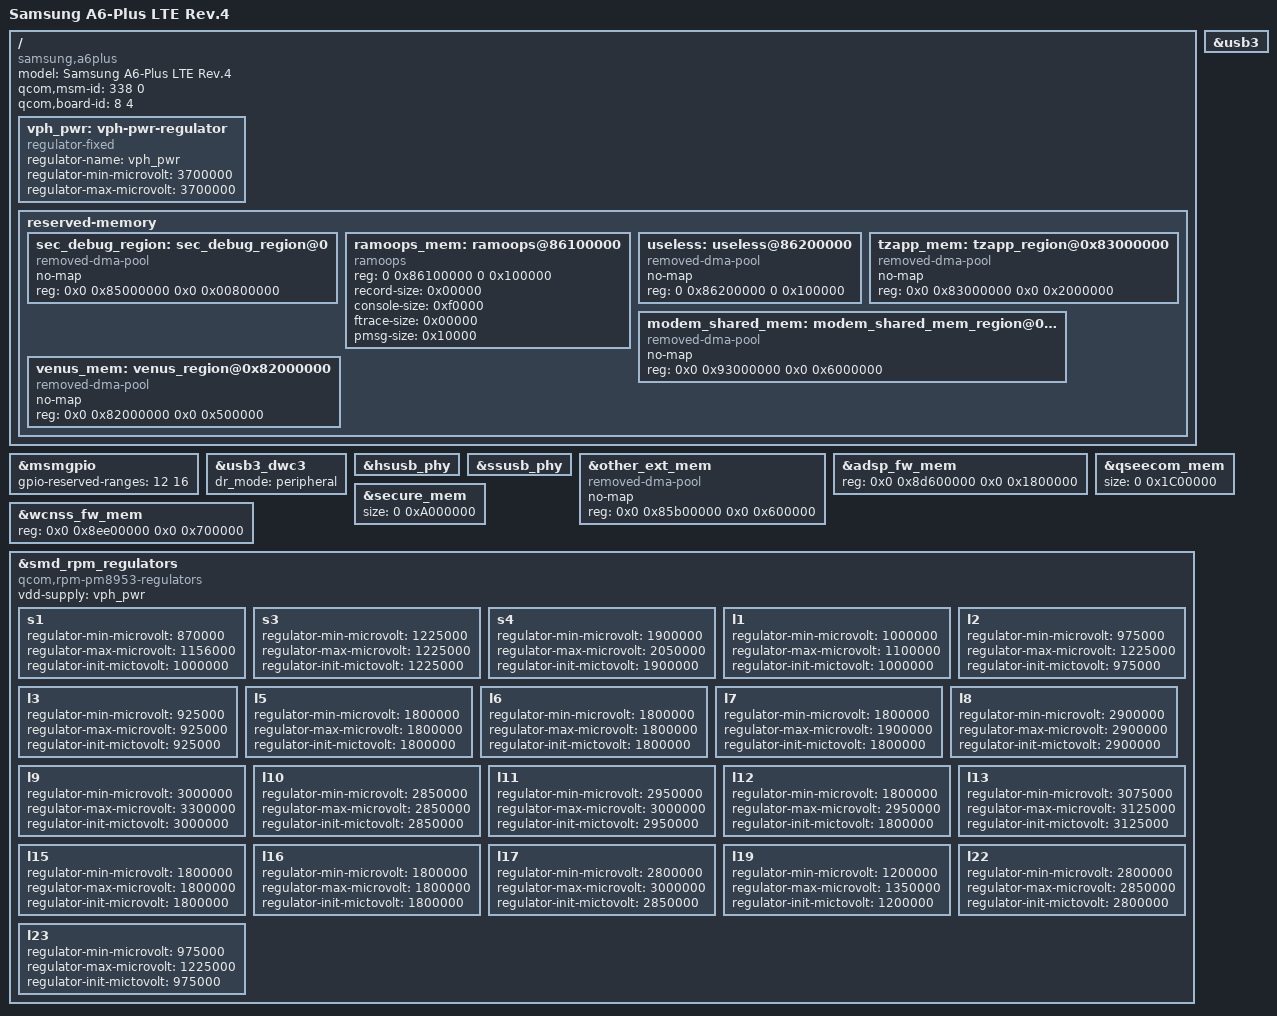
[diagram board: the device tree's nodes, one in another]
/* Copyright (c) 2017,2020, The Linux Foundation. All rights reserved.
 *
 * This program is free software; you can redistribute it and/or modify
 * it under the terms of the GNU General Public License version 2 and
 * only version 2 as published by the Free Software Foundation.
 *
 * This program is distributed in the hope that it will be useful,
 * but WITHOUT ANY WARRANTY; without even the implied warranty of
 * MERCHANTABILITY or FITNESS FOR A PARTICULAR PURPOSE.  See the
 * GNU General Public License for more details.
 */
/dts-v1/;

#include "msm8953.dtsi"
#include "pm8953.dtsi"

/ {
	model = "Samsung A6-Plus LTE Rev.4";
	compatible = "samsung,a6plus", "qcom,sdm450";
	qcom,msm-id = <338 0>;
	qcom,board-id = <8 4>;

	vph_pwr: vph-pwr-regulator {
		compatible = "regulator-fixed";
		regulator-name = "vph_pwr";
		regulator-min-microvolt = <3700000>;
		regulator-max-microvolt = <3700000>;
	};

	reserved-memory {
		/* CONFIG_SEC_DEBUG reserves 8MB */
		sec_debug_region: sec_debug_region@0 {
			compatible = "removed-dma-pool";
			no-map;
			reg = <0x0 0x85000000 0x0 0x00800000>;
		};

		ramoops_mem: ramoops@86100000 {
			compatible = "ramoops";
			reg = <0 0x86100000 0 0x100000>;
			record-size = <0x00000>;
			console-size = <0xf0000>;
			ftrace-size = <0x00000>;
			pmsg-size = <0x10000>;
		};

		useless: useless@86200000 {
			compatible = "removed-dma-pool";
			no-map;
			reg = <0 0x86200000 0 0x100000>;
		};

		tzapp_mem: tzapp_region@0x83000000 {
			compatible = "removed-dma-pool";
			no-map;
			reg = <0x0 0x83000000 0x0 0x2000000>;
		};

		modem_shared_mem: modem_shared_mem_region@0x93000000 {
			compatible = "removed-dma-pool";
			no-map;
			reg = <0x0 0x93000000 0x0 0x6000000>;
		};


		/delete-node/ venus_region@0;
		venus_mem: venus_region@0x82000000 {
			compatible = "removed-dma-pool";
			no-map;
			reg = <0x0 0x82000000 0x0 0x500000>;
		};

	};
};

&msmgpio {
	gpio-reserved-ranges = <12 16>; // Fingerprint sensor
};

&usb3 {
	status = "ok";
};

&usb3_dwc3 {
	dr_mode = "peripheral";
};

&hsusb_phy {
	status = "ok";
};

&ssusb_phy {
	status = "ok";
};

&other_ext_mem {
	compatible = "removed-dma-pool";
	no-map;
	reg = <0x0 0x85b00000 0x0 0x600000>;
};

&adsp_fw_mem {
	reg = <0x0 0x8d600000 0x0 0x1800000>;
};

&wcnss_fw_mem {
	reg = <0x0 0x8ee00000 0x0 0x700000>;
};

&qseecom_mem {
	size = <0 0x1C00000>;
};

&secure_mem {
	size = <0 0xA000000>;
};

&smd_rpm_regulators {
	compatible = "qcom,rpm-pm8953-regulators";

	vdd-supply = <&vph_pwr>;

	s1 {
		regulator-min-microvolt = <870000>;
		regulator-max-microvolt = <1156000>;
		regulator-init-mictovolt = <1000000>;
	};
	s3 {
		regulator-min-microvolt = <1225000>;
		regulator-max-microvolt = <1225000>;
		regulator-init-mictovolt = <1225000>;
	};
	s4 {
		regulator-min-microvolt = <1900000>;
		regulator-max-microvolt = <2050000>;
		regulator-init-mictovolt = <1900000>;
	};
	l1 {
		regulator-min-microvolt = <1000000>;
		regulator-max-microvolt = <1100000>;
		regulator-init-mictovolt = <1000000>;
	};
	l2 {
		regulator-min-microvolt = <975000>;
		regulator-max-microvolt = <1225000>;
		regulator-init-mictovolt = <975000>;
	};
	l3 {
		regulator-min-microvolt = <925000>;
		regulator-max-microvolt = <925000>;
		regulator-init-mictovolt = <925000>;
	};
	l5 {
		regulator-min-microvolt = <1800000>;
		regulator-max-microvolt = <1800000>;
		regulator-init-mictovolt = <1800000>;
	};
	l6 {
		regulator-min-microvolt = <1800000>;
		regulator-max-microvolt = <1800000>;
		regulator-init-mictovolt = <1800000>;
	};
	l7 {
		regulator-min-microvolt = <1800000>;
		regulator-max-microvolt = <1900000>;
		regulator-init-mictovolt = <1800000>;
	};
	l8 {
		regulator-min-microvolt = <2900000>;
		regulator-max-microvolt = <2900000>;
		regulator-init-mictovolt = <2900000>;
	};
	l9 {
		regulator-min-microvolt = <3000000>;
		regulator-max-microvolt = <3300000>;
		regulator-init-mictovolt = <3000000>;
	};
	l10 {
		regulator-min-microvolt = <2850000>;
		regulator-max-microvolt = <2850000>;
		regulator-init-mictovolt = <2850000>;
	};
	l11 {
		regulator-min-microvolt = <2950000>;
		regulator-max-microvolt = <3000000>;
		regulator-init-mictovolt = <2950000>;
	};
	l12 {
		regulator-min-microvolt = <1800000>;
		regulator-max-microvolt = <2950000>;
		regulator-init-mictovolt = <1800000>;
	};
	l13 {
		regulator-min-microvolt = <3075000>;
		regulator-max-microvolt = <3125000>;
		regulator-init-mictovolt = <3125000>;
	};
	l15 {
		regulator-min-microvolt = <1800000>;
		regulator-max-microvolt = <1800000>;
		regulator-init-microvolt = <1800000>;
	};
	l16 {
		regulator-min-microvolt = <1800000>;
		regulator-max-microvolt = <1800000>;
		regulator-init-mictovolt = <1800000>;
	};
	l17 {
		regulator-min-microvolt = <2800000>;
		regulator-max-microvolt = <3000000>;
		regulator-init-mictovolt = <2850000>;
	};
	l19 {
		regulator-min-microvolt = <1200000>;
		regulator-max-microvolt = <1350000>;
		regulator-init-mictovolt = <1200000>;
	};
	l22 {
		regulator-min-microvolt = <2800000>;
		regulator-max-microvolt = <2850000>;
		regulator-init-mictovolt = <2800000>;
	};
	l23 {
		regulator-min-microvolt = <975000>;
		regulator-max-microvolt = <1225000>;
		regulator-init-mictovolt = <975000>;
	};
};
